# iom480ae register map
Registers are 32-bit, access not given, no defined reset value unless marked. A register's access mark holds for its fields unless they carry their own. Addresses are absolute; registers are grouped by the start of their names; [hi:lo] are bit positions; {n}, {i} and the like mark numbered series; 'fields as' and 'values as' point back to an identical list.

## EPWM1
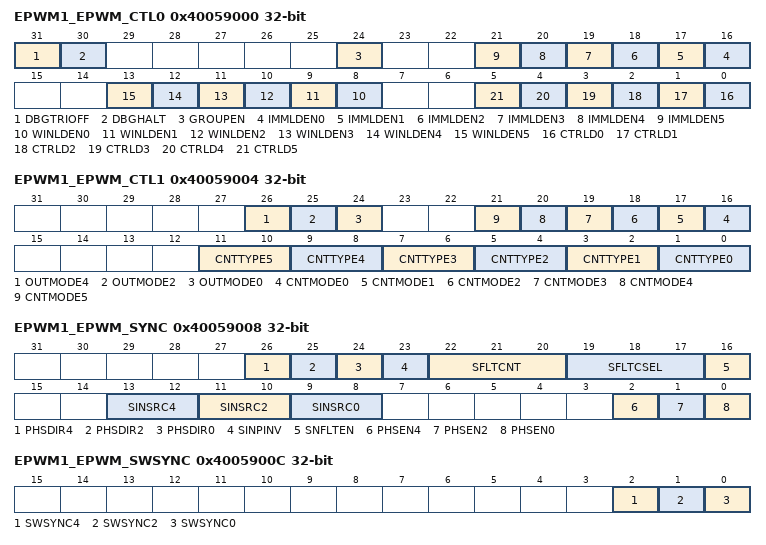
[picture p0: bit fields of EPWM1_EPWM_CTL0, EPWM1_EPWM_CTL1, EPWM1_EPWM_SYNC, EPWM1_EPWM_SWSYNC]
0x40059000 EPWM1_EPWM_CTL0
  [31] DBGTRIOFF, [30] DBGHALT, [24] GROUPEN, [n+16] IMMLDEN{n} (n=0..5), [n+8] WINLDEN{n} (n=0..5), [n] CTRLD{n} (n=0..5)
0x40059004 EPWM1_EPWM_CTL1
  [26] OUTMODE4, [25] OUTMODE2, [24] OUTMODE0, [n+16] CNTMODE{n} (n=0..5), [2n+1:2n] CNTTYPE{n} (n=0..5)
0x40059008 EPWM1_EPWM_SYNC
  [26] PHSDIR4, [25] PHSDIR2, [24] PHSDIR0, [23] SINPINV, [22:20] SFLTCNT, [19:17] SFLTCSEL, [16] SNFLTEN, [13:12] SINSRC4, [11:10] SINSRC2, [9:8] SINSRC0, [2] PHSEN4, [1] PHSEN2, [0] PHSEN0
0x4005900C EPWM1_EPWM_SWSYNC
  [2] SWSYNC4, [1] SWSYNC2, [0] SWSYNC0
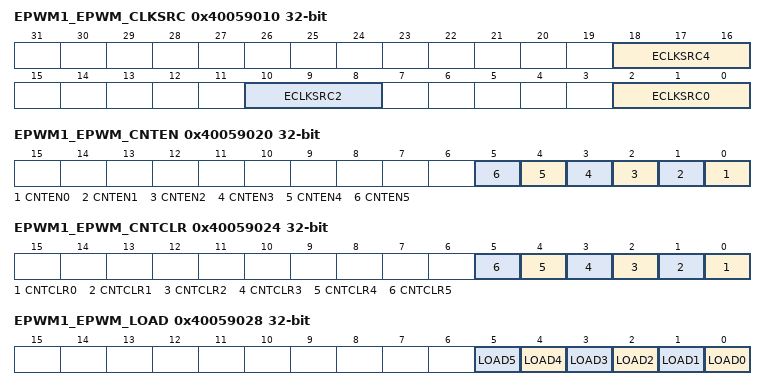
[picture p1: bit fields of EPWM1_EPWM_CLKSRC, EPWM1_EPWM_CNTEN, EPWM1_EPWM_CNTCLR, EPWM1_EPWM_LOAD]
0x40059010 EPWM1_EPWM_CLKSRC
  [18:16] ECLKSRC4, [10:8] ECLKSRC2, [2:0] ECLKSRC0
0x40059014 EPWM1_EPWM_CLKPSC0_1
  [11:0] CLKPSC
0x40059018 EPWM1_EPWM_CLKPSC2_3
  [11:0] CLKPSC
0x4005901C EPWM1_EPWM_CLKPSC4_5
  [11:0] CLKPSC
0x40059020 EPWM1_EPWM_CNTEN
  [n] CNTEN{n} (n=0..5)
0x40059024 EPWM1_EPWM_CNTCLR
  [n] CNTCLR{n} (n=0..5)
0x40059028 EPWM1_EPWM_LOAD
  [n] LOAD{n} (n=0..5)
{0x40059030+4i} EPWM1_EPWM_PERIOD{i} (i=0..5)
  [15:0] PERIOD
{0x40059050+4i} EPWM1_EPWM_CMPDAT{i} (i=0..5)
  [15:0] CMP
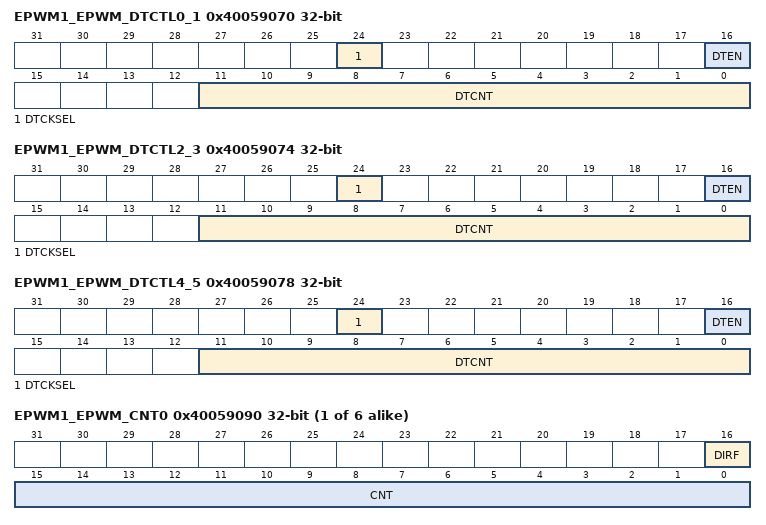
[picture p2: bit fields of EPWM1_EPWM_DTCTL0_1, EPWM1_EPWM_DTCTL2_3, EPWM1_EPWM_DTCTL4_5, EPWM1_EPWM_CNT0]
0x40059070 EPWM1_EPWM_DTCTL0_1
  [24] DTCKSEL, [16] DTEN, [11:0] DTCNT
0x40059074 EPWM1_EPWM_DTCTL2_3
  [24] DTCKSEL, [16] DTEN, [11:0] DTCNT
0x40059078 EPWM1_EPWM_DTCTL4_5
  [24] DTCKSEL, [16] DTEN, [11:0] DTCNT
0x40059080 EPWM1_EPWM_PHS0_1
  [15:0] PHS
0x40059084 EPWM1_EPWM_PHS2_3
  [15:0] PHS
0x40059088 EPWM1_EPWM_PHS4_5
  [15:0] PHS
{0x40059090+4i} EPWM1_EPWM_CNT{i} (i=0..5)
  [16] DIRF, [15:0] CNT
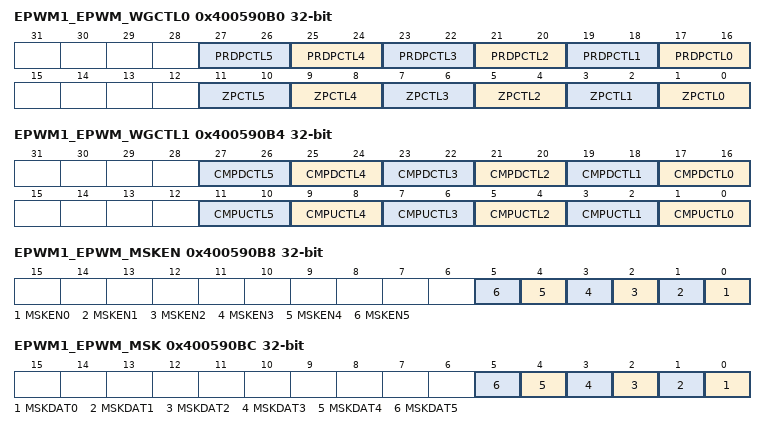
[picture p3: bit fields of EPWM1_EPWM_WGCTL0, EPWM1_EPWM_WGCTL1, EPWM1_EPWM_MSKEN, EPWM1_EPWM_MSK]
0x400590B0 EPWM1_EPWM_WGCTL0
  [2n+17:2n+16] PRDPCTL{n} (n=0..5), [2n+1:2n] ZPCTL{n} (n=0..5)
0x400590B4 EPWM1_EPWM_WGCTL1
  [2n+17:2n+16] CMPDCTL{n} (n=0..5), [2n+1:2n] CMPUCTL{n} (n=0..5)
0x400590B8 EPWM1_EPWM_MSKEN
  [n] MSKEN{n} (n=0..5)
0x400590BC EPWM1_EPWM_MSK
  [n] MSKDAT{n} (n=0..5)
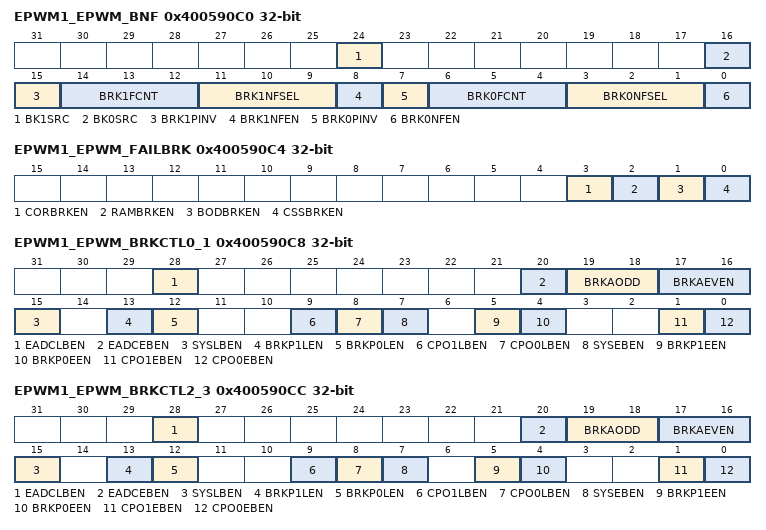
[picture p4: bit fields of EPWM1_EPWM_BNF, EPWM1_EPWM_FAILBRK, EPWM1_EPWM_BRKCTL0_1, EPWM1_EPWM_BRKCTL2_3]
0x400590C0 EPWM1_EPWM_BNF
  [24] BK1SRC, [16] BK0SRC, [15] BRK1PINV, [14:12] BRK1FCNT, [11:9] BRK1NFSEL, [8] BRK1NFEN, [7] BRK0PINV, [6:4] BRK0FCNT, [3:1] BRK0NFSEL, [0] BRK0NFEN
0x400590C4 EPWM1_EPWM_FAILBRK
  [3] CORBRKEN, [2] RAMBRKEN, [1] BODBRKEN, [0] CSSBRKEN
0x400590C8 EPWM1_EPWM_BRKCTL0_1
  [28] EADCLBEN, [20] EADCEBEN, [19:18] BRKAODD, [17:16] BRKAEVEN, [15] SYSLBEN, [13] BRKP1LEN, [12] BRKP0LEN, [9] CPO1LBEN, [8] CPO0LBEN, [7] SYSEBEN, [5] BRKP1EEN, [4] BRKP0EEN, [1] CPO1EBEN, [0] CPO0EBEN
0x400590CC EPWM1_EPWM_BRKCTL2_3
  fields as EPWM1_EPWM_BRKCTL0_1
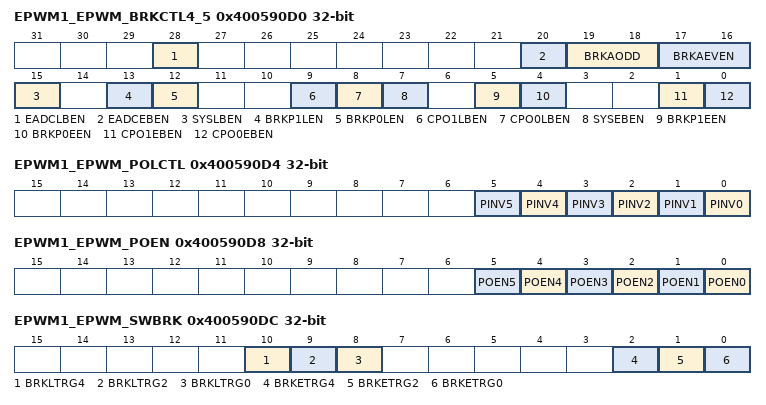
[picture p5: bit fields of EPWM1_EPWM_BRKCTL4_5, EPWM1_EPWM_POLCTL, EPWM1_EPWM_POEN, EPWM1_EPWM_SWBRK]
0x400590D0 EPWM1_EPWM_BRKCTL4_5
  fields as EPWM1_EPWM_BRKCTL0_1
0x400590D4 EPWM1_EPWM_POLCTL
  [n] PINV{n} (n=0..5)
0x400590D8 EPWM1_EPWM_POEN
  [n] POEN{n} (n=0..5)
0x400590DC EPWM1_EPWM_SWBRK
  [10] BRKLTRG4, [9] BRKLTRG2, [8] BRKLTRG0, [2] BRKETRG4, [1] BRKETRG2, [0] BRKETRG0
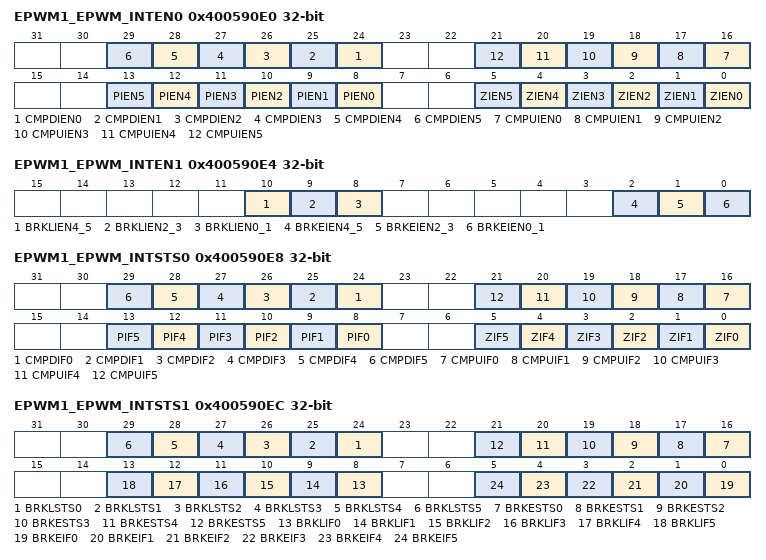
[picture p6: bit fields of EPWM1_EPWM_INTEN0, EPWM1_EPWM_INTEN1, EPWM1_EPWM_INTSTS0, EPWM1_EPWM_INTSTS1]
0x400590E0 EPWM1_EPWM_INTEN0
  [n+24] CMPDIEN{n} (n=0..5), [n+16] CMPUIEN{n} (n=0..5), [n+8] PIEN{n} (n=0..5), [n] ZIEN{n} (n=0..5)
0x400590E4 EPWM1_EPWM_INTEN1
  [10] BRKLIEN4_5, [9] BRKLIEN2_3, [8] BRKLIEN0_1, [2] BRKEIEN4_5, [1] BRKEIEN2_3, [0] BRKEIEN0_1
0x400590E8 EPWM1_EPWM_INTSTS0
  [n+24] CMPDIF{n} (n=0..5), [n+16] CMPUIF{n} (n=0..5), [n+8] PIF{n} (n=0..5), [n] ZIF{n} (n=0..5)
0x400590EC EPWM1_EPWM_INTSTS1
  [n+24] BRKLSTS{n} (n=0..5), [n+16] BRKESTS{n} (n=0..5), [n+8] BRKLIF{n} (n=0..5), [n] BRKEIF{n} (n=0..5)
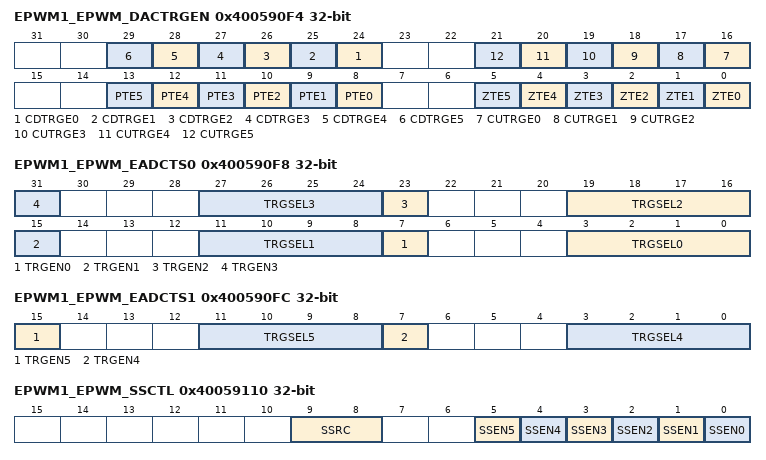
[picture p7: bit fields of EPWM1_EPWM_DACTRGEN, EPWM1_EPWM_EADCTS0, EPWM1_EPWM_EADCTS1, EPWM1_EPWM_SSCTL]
0x400590F4 EPWM1_EPWM_DACTRGEN
  [n+24] CDTRGE{n} (n=0..5), [n+16] CUTRGE{n} (n=0..5), [n+8] PTE{n} (n=0..5), [n] ZTE{n} (n=0..5)
0x400590F8 EPWM1_EPWM_EADCTS0
  [8n+7] TRGEN{n} (n=0..3), [8n+3:8n] TRGSEL{n} (n=0..3)
0x400590FC EPWM1_EPWM_EADCTS1
  [15] TRGEN5, [11:8] TRGSEL5, [7] TRGEN4, [3:0] TRGSEL4
0x40059100 EPWM1_EPWM_FTCMPDAT0_1
  [15:0] FTCMP
0x40059104 EPWM1_EPWM_FTCMPDAT2_3
  [15:0] FTCMP
0x40059108 EPWM1_EPWM_FTCMPDAT4_5
  [15:0] FTCMP
0x40059110 EPWM1_EPWM_SSCTL
  [9:8] SSRC, [n] SSEN{n} (n=0..5)
0x40059114 EPWM1_EPWM_SSTRG
  [0] CNTSEN
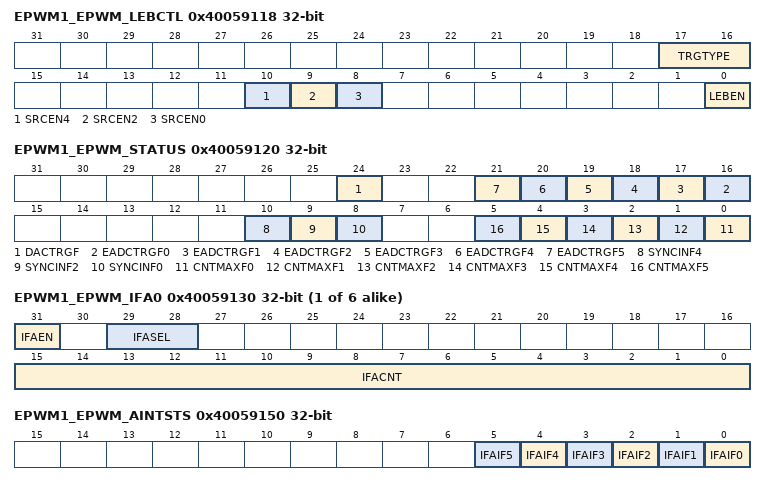
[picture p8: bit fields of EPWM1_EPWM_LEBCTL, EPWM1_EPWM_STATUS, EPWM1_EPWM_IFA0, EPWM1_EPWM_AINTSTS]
0x40059118 EPWM1_EPWM_LEBCTL
  [17:16] TRGTYPE, [10] SRCEN4, [9] SRCEN2, [8] SRCEN0, [0] LEBEN
0x4005911C EPWM1_EPWM_LEBCNT
  [8:0] LEBCNT
0x40059120 EPWM1_EPWM_STATUS
  [24] DACTRGF, [n+16] EADCTRGF{n} (n=0..5), [10] SYNCINF4, [9] SYNCINF2, [8] SYNCINF0, [n] CNTMAXF{n} (n=0..5)
{0x40059130+4i} EPWM1_EPWM_IFA{i} (i=0..5)
  [31] IFAEN, [29:28] IFASEL, [15:0] IFACNT
0x40059150 EPWM1_EPWM_AINTSTS
  [n] IFAIF{n} (n=0..5)
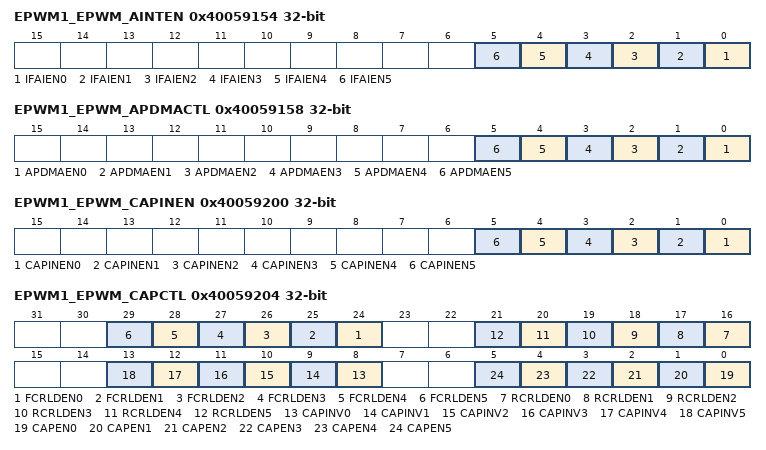
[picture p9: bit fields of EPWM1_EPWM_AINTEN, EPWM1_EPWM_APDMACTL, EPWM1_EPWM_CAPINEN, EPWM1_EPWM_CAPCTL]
0x40059154 EPWM1_EPWM_AINTEN
  [n] IFAIEN{n} (n=0..5)
0x40059158 EPWM1_EPWM_APDMACTL
  [n] APDMAEN{n} (n=0..5)
0x40059200 EPWM1_EPWM_CAPINEN
  [n] CAPINEN{n} (n=0..5)
0x40059204 EPWM1_EPWM_CAPCTL
  [n+24] FCRLDEN{n} (n=0..5), [n+16] RCRLDEN{n} (n=0..5), [n+8] CAPINV{n} (n=0..5), [n] CAPEN{n} (n=0..5)
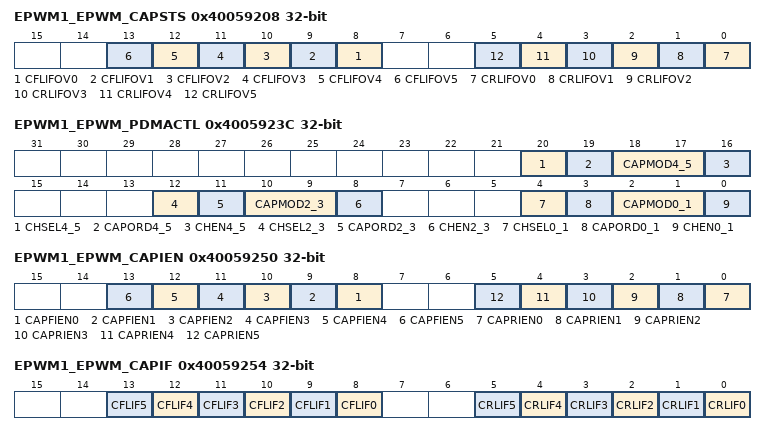
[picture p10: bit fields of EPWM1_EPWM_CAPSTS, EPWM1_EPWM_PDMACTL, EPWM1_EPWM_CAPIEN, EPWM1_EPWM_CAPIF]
0x40059208 EPWM1_EPWM_CAPSTS
  [n+8] CFLIFOV{n} (n=0..5), [n] CRLIFOV{n} (n=0..5)
{0x4005920C+8i} EPWM1_EPWM_RCAPDAT{i} (i=0..5)
  [15:0] RCAPDAT
{0x40059210+8i} EPWM1_EPWM_FCAPDAT{i} (i=0..5)
  [15:0] FCAPDAT
0x4005923C EPWM1_EPWM_PDMACTL
  [20] CHSEL4_5, [19] CAPORD4_5, [18:17] CAPMOD4_5, [16] CHEN4_5, [12] CHSEL2_3, [11] CAPORD2_3, [10:9] CAPMOD2_3, [8] CHEN2_3, [4] CHSEL0_1, [3] CAPORD0_1, [2:1] CAPMOD0_1, [0] CHEN0_1
0x40059240 EPWM1_EPWM_PDMACAP0_1
  [15:0] CAPBUF
0x40059244 EPWM1_EPWM_PDMACAP2_3
  [15:0] CAPBUF
0x40059248 EPWM1_EPWM_PDMACAP4_5
  [15:0] CAPBUF
0x40059250 EPWM1_EPWM_CAPIEN
  [n+8] CAPFIEN{n} (n=0..5), [n] CAPRIEN{n} (n=0..5)
0x40059254 EPWM1_EPWM_CAPIF
  [n+8] CFLIF{n} (n=0..5), [n] CRLIF{n} (n=0..5)
{0x40059304+4i} EPWM1_EPWM_PBUF{i} (i=0..5)
  [15:0] PBUF
{0x4005931C+4i} EPWM1_EPWM_CMPBUF{i} (i=0..5)
  [15:0] CMPBUF
0x40059334 EPWM1_EPWM_CPSCBUF0_1
  [11:0] CPSCBUF
0x40059338 EPWM1_EPWM_CPSCBUF2_3
  [11:0] CPSCBUF
0x4005933C EPWM1_EPWM_CPSCBUF4_5
  [11:0] CPSCBUF
0x40059340 EPWM1_EPWM_FTCBUF0_1
  [15:0] FTCMPBUF
0x40059344 EPWM1_EPWM_FTCBUF2_3
  [15:0] FTCMPBUF
0x40059348 EPWM1_EPWM_FTCBUF4_5
  [15:0] FTCMPBUF
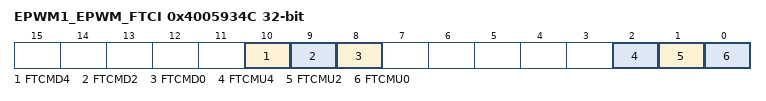
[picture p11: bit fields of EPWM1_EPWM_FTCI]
0x4005934C EPWM1_EPWM_FTCI
  [10] FTCMD4, [9] FTCMD2, [8] FTCMD0, [2] FTCMU4, [1] FTCMU2, [0] FTCMU0
